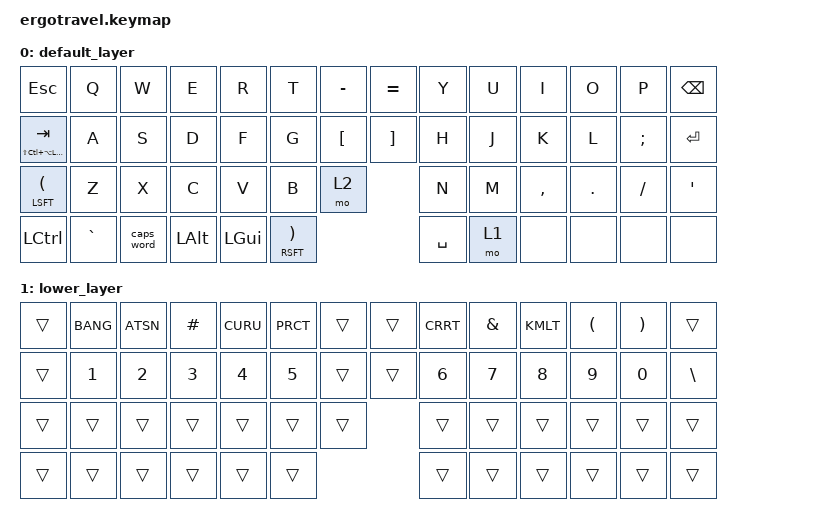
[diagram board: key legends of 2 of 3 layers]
#include <behaviors.dtsi>
#include <dt-bindings/zmk/keys.h>
#include <dt-bindings/zmk/bt.h>

#define SPACEL &mt LSFT LPAR
#define SPACER &mt RSFT RPAR
#define SUPER &mt LS(LC(LA(LCMD))) TAB

&caps_word {
    continue-list = <UNDERSCORE MINUS>;
};

/ {
	keymap {
		compatible = "zmk,keymap";

		default_layer {
// ------------------------------------------------------------------------------------------------------------
// |  TAB  |  Q  |  W  |  E   |  R   |  T   |                   |  Y   |  U    |  I    |  O   |   P   |   -   |
// |  CTRL |  A  |  S  |  D   |  F   |  G   |                   |  H   |  J    |  K    |  L   |   ;   |   '   |
// | SHIFT |  Z  |  X  |  C   |  V   |  B   |   "["  |  |  "]"  |  N   |  M    |  ,    |  .   |   /   | SHIFT |
//                     | ALT  | GUI  | LOWER|  SPACE |  | ENTER | RAISE| BSPC  | GUI   |
			bindings = <
&kp ESC  &kp Q     &kp W     &kp E     &kp R     &kp T     &kp MINUS       &kp EQL   &kp Y     &kp U     &kp I     &kp O     &kp P     &kp BKSP
SUPER    &kp A     &kp S     &kp D     &kp F     &kp G     &kp LBKT        &kp RBKT  &kp H     &kp J     &kp K     &kp L     &kp SCLN  &kp RET
SPACEL   &kp Z     &kp X     &kp C     &kp V     &kp B     &mo 2                     &kp N     &kp M     &kp CMMA  &kp DOT   &kp FSLH  &kp QUOT
&kp LCTL &kp GRAV  &caps_word &kp LALT    &kp LGUI    SPACER                  &kp SPC      &mo 1         &none     &none     &none     &none
			>;
		};

		lower_layer {
// ------------------------------------------------------------------------------------------------------------
// |  F1   |  F2 |  F3 |  F4  |  F5  |  F6  |                   |  F7  |  F8   |  F9   |  F10 |  F11  |  F12  |
// |   `   |  !  |  @  |  #   |  $   |  %   |                   |  ^   |  &    |  *    |  (   |   )   |   ~   |
// |       |     |     |      |      |      |        |  |       |      |  _    |  +    |  {   |   }   |  "|"  |
//                     |      |      |      |        |  |       |      |       |       |
			bindings = <
&trans   &kp BANG  &kp ATSN  &kp HASH  &kp CURU  &kp PRCT  &trans          &trans    &kp CRRT  &kp AMPS  &kp KMLT  &kp LPRN  &kp RPRN  &trans
&trans   &kp NUM_1 &kp NUM_2 &kp NUM_3 &kp NUM_4 &kp NUM_5 &trans          &trans    &kp NUM_6 &kp NUM_7 &kp NUM_8 &kp NUM_9 &kp NUM_0 &kp BSLH
&trans   &trans    &trans    &trans    &trans    &trans    &trans                    &trans    &trans    &trans    &trans    &trans    &trans
&trans   &trans    &trans    &trans         &trans     &trans                  &trans      &trans        &trans    &trans    &trans    &trans
			>;
		};

		raise_layer {
// ------------------------------------------------------------------------------------------------------------
// |  F1   |  F2 |  F3 |  F4  |  F5  |  F6  |                   |  F7  |  F8   |  F9   |  F10 |  F11  |  F12  |
// |   `   |  !  |  @  |  #   |  $   |  %   |                   |  ^   |  &    |  *    |  (   |   )   |   ~   |
// |       |     |     |      |      |      |        |  |       |      |  _    |  +    |  {   |   }   |  "|"  |
//                     |      |      |      |        |  |       |      |       |       |
			bindings = <
&bt BT_CLR &bt BT_SEL 0 &bt BT_SEL 1 &bt BT_SEL 2 &bt BT_SEL 3 &trans      &trans    &trans    &trans    &trans    &trans    &trans    &trans
&trans   &trans    &trans    &trans    &trans    &trans    &trans          &trans    &trans    &kp LARW  &kp DARW  &kp UARW  &kp RARW  &trans
&trans   &trans    &trans    &trans    &trans    &trans    &trans                    &trans    &trans    &trans    &trans    &trans    &trans
&trans   &trans    &trans    &trans         &trans     &trans                  &trans      &trans        &trans    &trans    &trans    &trans
			>;
		};
	};
};
